AUTOSAR XML (schema 4.0)
package /BcmSystem/SwComponentTypes
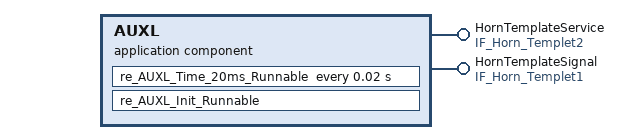
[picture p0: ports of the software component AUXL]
  application sw component type AUXL
    provide port HornTemplateService: provided-interface=IF_Horn_Templet2
    provide port HornTemplateSignal: provided-interface=IF_Horn_Templet1
    behavior AUXL_IB: handle-termination-and-restart=NO-SUPPORT
      init event ie_AUXL_Init_Runnable: start-on-event=re_AUXL_Init_Runnable
      timing event te_AUXL_Time_20ms_Runnable: start-on-event=re_AUXL_Time_20ms_Runnable, period=0.02
      runnable re_AUXL_Init_Runnable: symbol=AUXL_Init_Runnable
      runnable re_AUXL_Time_20ms_Runnable: symbol=AUXL_Time_20ms_Runnable
package /BcmSystem/SwImplementations
  swc implementation SwcImpAUXL: programming-language=C, sw-version=1.0.0, vendor-id=0, behavior=AUXL_IB
    code-descriptors:
      code CodeAUXL: artifact-descriptors=autosar-engineering-object={short-label=SwSrcAUXL, category=SWSRC}
    resource consumption ResourceConAUXL
      21 x memory section:
        CODE: sw-addrmethod=CODE
        CONST_16: alignment=16, size=2, sw-addrmethod=CONST
        CONST_32: alignment=32, size=4, sw-addrmethod=CONST
        CONST_8: alignment=8, size=1, sw-addrmethod=CONST
        CONST_BOOLEAN: alignment=BOOLEAN, size=1, sw-addrmethod=CONST
        CONST_UNSPECIFIED: alignment=UNSPECIFIED, size=0, sw-addrmethod=CONST
        VAR_CLEARED_16: alignment=16, size=2, sw-addrmethod=VAR_CLEARED
        VAR_CLEARED_32: alignment=32, size=4, sw-addrmethod=VAR_CLEARED
        VAR_CLEARED_8: alignment=8, size=1, sw-addrmethod=VAR_CLEARED
        VAR_CLEARED_BOOLEAN: alignment=BOOLEAN, size=1, sw-addrmethod=VAR_CLEARED
        VAR_CLEARED_UNSPECIFIED: alignment=UNSPECIFIED, size=0, sw-addrmethod=VAR_CLEARED
        VAR_INIT_16: alignment=16, size=2, sw-addrmethod=VAR_INIT
        VAR_INIT_32: alignment=32, size=4, sw-addrmethod=VAR_INIT
        VAR_INIT_8: alignment=8, size=1, sw-addrmethod=VAR_INIT
        VAR_INIT_BOOLEAN: alignment=BOOLEAN, size=1, sw-addrmethod=VAR_INIT
        VAR_INIT_UNSPECIFIED: alignment=UNSPECIFIED, size=0, sw-addrmethod=VAR_INIT
        VAR_POWER_ON_CLEARED_16: alignment=16, size=2, sw-addrmethod=VAR_POWER_ON_CLEARED
        VAR_POWER_ON_CLEARED_32: alignment=32, size=4, sw-addrmethod=VAR_POWER_ON_CLEARED
        VAR_POWER_ON_CLEARED_8: alignment=8, size=1, sw-addrmethod=VAR_POWER_ON_CLEARED
        VAR_POWER_ON_CLEARED_BOOLEAN: alignment=BOOLEAN, size=1, sw-addrmethod=VAR_POWER_ON_CLEARED
        VAR_POWER_ON_CLEARED_UNSPECIFIED: alignment=UNSPECIFIED, size=0, sw-addrmethod=VAR_POWER_ON_CLEARED
